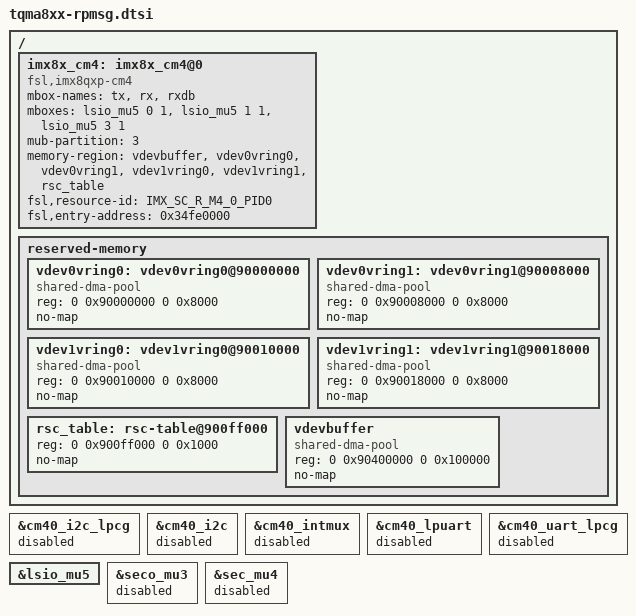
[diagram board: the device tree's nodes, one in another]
// SPDX-License-Identifier: (GPL-2.0-or-later OR MIT)
/*
 * Copyright (c) 2021-2023 TQ-Systems GmbH <linux@ew.tq-group.com>,
 * D-82229 Seefeld, Germany.
 * Author: Alexander Stein
 */

/ {
	imx8x_cm4: imx8x_cm4@0 {
		compatible = "fsl,imx8qxp-cm4";
		mbox-names = "tx", "rx", "rxdb";
		mboxes = <&lsio_mu5 0 1
			  &lsio_mu5 1 1
			  &lsio_mu5 3 1>;
		/*
		 * partition ID the M4 is running in,
		 * assigned via imx-mkimage when building bootstream
		 */
		mub-partition = <3>;
		memory-region = <&vdevbuffer>, <&vdev0vring0>, <&vdev0vring1>,
				<&vdev1vring0>, <&vdev1vring1>, <&rsc_table>;
		fsl,resource-id = <IMX_SC_R_M4_0_PID0>;
		fsl,entry-address = <0x34fe0000>;
	};

	reserved-memory {
		vdev0vring0: vdev0vring0@90000000 {
			compatible = "shared-dma-pool";
			reg = <0 0x90000000 0 0x8000>;
			no-map;
		};

		vdev0vring1: vdev0vring1@90008000 {
			compatible = "shared-dma-pool";
			reg = <0 0x90008000 0 0x8000>;
			no-map;
		};

		vdev1vring0: vdev1vring0@90010000 {
			compatible = "shared-dma-pool";
			reg = <0 0x90010000 0 0x8000>;
			no-map;
		};

		vdev1vring1: vdev1vring1@90018000 {
			compatible = "shared-dma-pool";
			reg = <0 0x90018000 0 0x8000>;
			no-map;
		};

		rsc_table: rsc-table@900ff000 {
			reg = <0 0x900ff000 0 0x1000>;
			no-map;
		};

		vdevbuffer: vdevbuffer {
			compatible = "shared-dma-pool";
			reg = <0 0x90400000 0 0x100000>;
			no-map;
		};
	};
};

&cm40_i2c_lpcg {
	status = "disabled";
};

&cm40_i2c {
	status = "disabled";
};

&cm40_intmux {
	status = "disabled";
};

&cm40_lpuart {
	status = "disabled";
};

&cm40_uart_lpcg {
	status = "disabled";
};

&lsio_mu5 {
	status = "okay";
};

&seco_mu3 {
	status = "disabled";
};

&sec_mu4 {
	status = "disabled";
};
